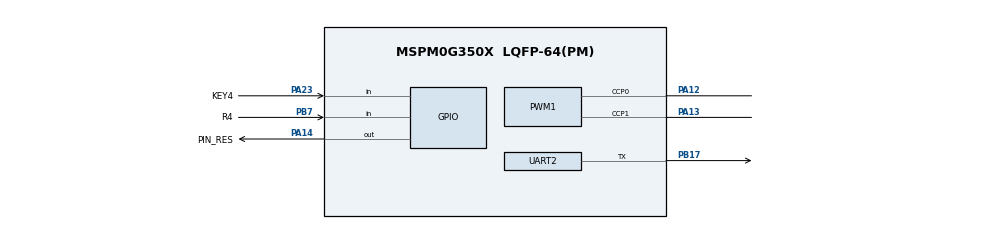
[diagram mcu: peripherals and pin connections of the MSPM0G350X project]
/**
 * @cliArgs --device "MSPM0G350X" --part "Default" --package "LQFP-64(PM)" --product "mspm0_sdk@2.05.01.01"
 * @versions {"tool":"1.24.0+4110"}
 */

/**
 * Import the modules used in this configuration.
 */
const GPIO   = scripting.addModule("/ti/driverlib/GPIO", {}, false);
const GPIO1  = GPIO.addInstance();
const GPIO2  = GPIO.addInstance();
const GPIO3  = GPIO.addInstance();
const GPIO4  = GPIO.addInstance();
const PWM    = scripting.addModule("/ti/driverlib/PWM", {}, false);
const PWM1   = PWM.addInstance();
const SPI    = scripting.addModule("/ti/driverlib/SPI", {}, false);
const SPI1   = SPI.addInstance();
const SYSCTL = scripting.addModule("/ti/driverlib/SYSCTL");
const TIMER  = scripting.addModule("/ti/driverlib/TIMER", {}, false);
const TIMER1 = TIMER.addInstance();
const UART   = scripting.addModule("/ti/driverlib/UART", {}, false);
const UART1  = UART.addInstance();
const UART2  = UART.addInstance();

/**
 * Write custom configuration values to the imported modules.
 */
const divider7       = system.clockTree["PLL_PDIV"];
divider7.divideValue = 2;

const divider9       = system.clockTree["UDIV"];
divider9.divideValue = 2;

const multiplier2         = system.clockTree["PLL_QDIV"];
multiplier2.multiplyValue = 5;

const mux8       = system.clockTree["HSCLKMUX"];
mux8.inputSelect = "HSCLKMUX_SYSPLL2X";

GPIO1.$name                         = "GPIO_OLED";
GPIO1.associatedPins[0].$name       = "PIN_RES";
GPIO1.associatedPins[0].pin.$assign = "PA14";

const Board = scripting.addModule("/ti/driverlib/Board", {}, false);

GPIO2.$name                          = "xunji";
GPIO2.associatedPins.create(8);
GPIO2.associatedPins[0].$name        = "L4";
GPIO2.associatedPins[0].direction    = "INPUT";
GPIO2.associatedPins[0].assignedPort = "PORTA";
GPIO2.associatedPins[0].assignedPin  = "0";
GPIO2.associatedPins[1].$name        = "L3";
GPIO2.associatedPins[1].direction    = "INPUT";
GPIO2.associatedPins[1].assignedPort = "PORTA";
GPIO2.associatedPins[1].assignedPin  = "1";
GPIO2.associatedPins[2].$name        = "L2";
GPIO2.associatedPins[2].direction    = "INPUT";
GPIO2.associatedPins[2].assignedPort = "PORTA";
GPIO2.associatedPins[2].assignedPin  = "28";
GPIO2.associatedPins[3].$name        = "L1";
GPIO2.associatedPins[3].direction    = "INPUT";
GPIO2.associatedPins[3].assignedPort = "PORTA";
GPIO2.associatedPins[3].assignedPin  = "27";
GPIO2.associatedPins[4].$name        = "R1";
GPIO2.associatedPins[4].direction    = "INPUT";
GPIO2.associatedPins[4].assignedPort = "PORTA";
GPIO2.associatedPins[4].assignedPin  = "26";
GPIO2.associatedPins[5].$name        = "R2";
GPIO2.associatedPins[5].direction    = "INPUT";
GPIO2.associatedPins[5].assignedPort = "PORTA";
GPIO2.associatedPins[5].assignedPin  = "25";
GPIO2.associatedPins[6].$name        = "R3";
GPIO2.associatedPins[6].direction    = "INPUT";
GPIO2.associatedPins[6].assignedPort = "PORTA";
GPIO2.associatedPins[6].assignedPin  = "24";
GPIO2.associatedPins[7].$name        = "R4";
GPIO2.associatedPins[7].direction    = "INPUT";
GPIO2.associatedPins[7].assignedPin  = "7";
GPIO2.associatedPins[7].assignedPort = "PORTB";
GPIO2.associatedPins[7].pin.$assign  = "PB7";

GPIO3.$name                          = "motorin";
GPIO3.associatedPins.create(5);
GPIO3.associatedPins[0].$name        = "AIN1";
GPIO3.associatedPins[0].assignedPort = "PORTB";
GPIO3.associatedPins[0].assignedPin  = "8";
GPIO3.associatedPins[1].$name        = "AIN2";
GPIO3.associatedPins[1].assignedPort = "PORTB";
GPIO3.associatedPins[1].assignedPin  = "9";
GPIO3.associatedPins[2].$name        = "BIN1";
GPIO3.associatedPins[2].assignedPort = "PORTA";
GPIO3.associatedPins[2].assignedPin  = "21";
GPIO3.associatedPins[3].$name        = "BIN2";
GPIO3.associatedPins[3].assignedPort = "PORTA";
GPIO3.associatedPins[3].assignedPin  = "22";
GPIO3.associatedPins[4].$name        = "STBY";
GPIO3.associatedPins[4].assignedPort = "PORTA";
GPIO3.associatedPins[4].assignedPin  = "16";

GPIO4.$name                              = "KEYS";
GPIO4.associatedPins.create(4);
GPIO4.associatedPins[0].direction        = "INPUT";
GPIO4.associatedPins[0].assignedPort     = "PORTA";
GPIO4.associatedPins[0].assignedPin      = "2";
GPIO4.associatedPins[0].$name            = "KEY1";
GPIO4.associatedPins[0].internalResistor = "PULL_UP";
GPIO4.associatedPins[1].direction        = "INPUT";
GPIO4.associatedPins[1].$name            = "KEY2";
GPIO4.associatedPins[1].assignedPort     = "PORTB";
GPIO4.associatedPins[1].assignedPin      = "19";
GPIO4.associatedPins[1].internalResistor = "PULL_UP";
GPIO4.associatedPins[2].direction        = "INPUT";
GPIO4.associatedPins[2].assignedPort     = "PORTB";
GPIO4.associatedPins[2].$name            = "KEY3";
GPIO4.associatedPins[2].assignedPin      = "20";
GPIO4.associatedPins[3].$name            = "KEY4";
GPIO4.associatedPins[3].direction        = "INPUT";
GPIO4.associatedPins[3].assignedPort     = "PORTA";
GPIO4.associatedPins[3].assignedPin      = "23";
GPIO4.associatedPins[3].pin.$assign      = "PA23";

PWM1.$name                              = "motorAB";
PWM1.timerCount                         = 32000;
PWM1.pwmMode                            = "EDGE_ALIGN_UP";
PWM1.peripheral.ccp0Pin.$assign         = "PA12";
PWM1.peripheral.ccp1Pin.$assign         = "PA13";
PWM1.PWM_CHANNEL_0.$name                = "ti_driverlib_pwm_PWMTimerCC0";
PWM1.PWM_CHANNEL_1.$name                = "ti_driverlib_pwm_PWMTimerCC1";
PWM1.ccp0PinConfig.direction            = scripting.forceWrite("OUTPUT");
PWM1.ccp0PinConfig.hideOutputInversion  = scripting.forceWrite(false);
PWM1.ccp0PinConfig.onlyInternalResistor = scripting.forceWrite(false);
PWM1.ccp0PinConfig.passedPeripheralType = scripting.forceWrite("Digital");
PWM1.ccp0PinConfig.$name                = "ti_driverlib_gpio_GPIOPinGeneric5";
PWM1.ccp1PinConfig.direction            = scripting.forceWrite("OUTPUT");
PWM1.ccp1PinConfig.hideOutputInversion  = scripting.forceWrite(false);
PWM1.ccp1PinConfig.onlyInternalResistor = scripting.forceWrite(false);
PWM1.ccp1PinConfig.passedPeripheralType = scripting.forceWrite("Digital");
PWM1.ccp1PinConfig.$name                = "ti_driverlib_gpio_GPIOPinGeneric6";

SPI1.$name                              = "SPI_OLED";
SPI1.targetBitRate                      = 10000000;
SPI1.direction                          = "PICO";
SPI1.enableCDMode                       = true;
SPI1.sclkPinConfig.direction            = scripting.forceWrite("OUTPUT");
SPI1.sclkPinConfig.onlyInternalResistor = scripting.forceWrite(false);
SPI1.sclkPinConfig.passedPeripheralType = scripting.forceWrite("Digital");
SPI1.sclkPinConfig.$name                = "ti_driverlib_gpio_GPIOPinGeneric0";
SPI1.mosiPinConfig.direction            = scripting.forceWrite("OUTPUT");
SPI1.mosiPinConfig.hideOutputInversion  = scripting.forceWrite(false);
SPI1.mosiPinConfig.onlyInternalResistor = scripting.forceWrite(false);
SPI1.mosiPinConfig.passedPeripheralType = scripting.forceWrite("Digital");
SPI1.mosiPinConfig.$name                = "ti_driverlib_gpio_GPIOPinGeneric2";
SPI1.cs0PinConfig.direction             = scripting.forceWrite("OUTPUT");
SPI1.cs0PinConfig.hideOutputInversion   = scripting.forceWrite(false);
SPI1.cs0PinConfig.onlyInternalResistor  = scripting.forceWrite(false);
SPI1.cs0PinConfig.passedPeripheralType  = scripting.forceWrite("Digital");
SPI1.cs0PinConfig.$name                 = "ti_driverlib_gpio_GPIOPinGeneric4";
SPI1.cs3PinConfig.$name                 = "ti_driverlib_gpio_GPIOPinGeneric3";

SYSCTL.forceDefaultClkConfig = true;
SYSCTL.clockTreeEn           = true;
scripting.suppress("For best practices when the CPUCLK is running at 32MHz and above, clear the flash status bit using DL_FlashCTL_executeClearStatus\\(\\) before executing any flash operation\\. Otherwise there may be false positives\\.", SYSCTL);

TIMER1.$name            = "TIM_EncoderA";
TIMER1.timerClkPrescale = 256;
TIMER1.timerPeriod      = "100ms";
TIMER1.interrupts       = ["ZERO"];

UART1.$name                            = "UART_WIT";
UART1.targetBaudRate                   = 115200;
UART1.direction                        = "RX";
UART1.enableFIFO                       = true;
UART1.rxTimeoutValue                   = 1;
UART1.enabledInterrupts                = ["RX_TIMEOUT_ERROR"];
UART1.enabledDMARXTriggers             = "DL_UART_DMA_INTERRUPT_RX";
UART1.rxPinConfig.hideOutputInversion  = scripting.forceWrite(false);
UART1.rxPinConfig.onlyInternalResistor = scripting.forceWrite(false);
UART1.rxPinConfig.passedPeripheralType = scripting.forceWrite("Digital");
UART1.rxPinConfig.$name                = "ti_driverlib_gpio_GPIOPinGeneric1";
UART1.DMA_CHANNEL_RX.$name             = "DMA_WIT";
UART1.DMA_CHANNEL_RX.srcLength         = "BYTE";
UART1.DMA_CHANNEL_RX.dstLength         = "BYTE";
UART1.DMA_CHANNEL_RX.addressMode       = "f2b";

UART2.$name                            = "UART_0";
UART2.targetBaudRate                   = 115200;
UART2.peripheral.txPin.$assign         = "PB17";
UART2.txPinConfig.direction            = scripting.forceWrite("OUTPUT");
UART2.txPinConfig.hideOutputInversion  = scripting.forceWrite(false);
UART2.txPinConfig.onlyInternalResistor = scripting.forceWrite(false);
UART2.txPinConfig.passedPeripheralType = scripting.forceWrite("Digital");
UART2.txPinConfig.$name                = "ti_driverlib_gpio_GPIOPinGeneric7";
UART2.rxPinConfig.hideOutputInversion  = scripting.forceWrite(false);
UART2.rxPinConfig.onlyInternalResistor = scripting.forceWrite(false);
UART2.rxPinConfig.passedPeripheralType = scripting.forceWrite("Digital");
UART2.rxPinConfig.$name                = "ti_driverlib_gpio_GPIOPinGeneric8";

/**
 * Pinmux solution for unlocked pins/peripherals. This ensures that minor changes to the automatic solver in a future
 * version of the tool will not impact the pinmux you originally saw.  These lines can be completely deleted in order to
 * re-solve from scratch.
 */
Board.peripheral.$suggestSolution                = "DEBUGSS";
Board.peripheral.swclkPin.$suggestSolution       = "PA20";
Board.peripheral.swdioPin.$suggestSolution       = "PA19";
GPIO2.associatedPins[0].pin.$suggestSolution     = "PA0";
GPIO2.associatedPins[1].pin.$suggestSolution     = "PA1";
GPIO2.associatedPins[2].pin.$suggestSolution     = "PA28";
GPIO2.associatedPins[3].pin.$suggestSolution     = "PA27";
GPIO2.associatedPins[4].pin.$suggestSolution     = "PA26";
GPIO2.associatedPins[5].pin.$suggestSolution     = "PA25";
GPIO2.associatedPins[6].pin.$suggestSolution     = "PA24";
GPIO3.associatedPins[0].pin.$suggestSolution     = "PB8";
GPIO3.associatedPins[1].pin.$suggestSolution     = "PB9";
GPIO3.associatedPins[2].pin.$suggestSolution     = "PA21";
GPIO3.associatedPins[3].pin.$suggestSolution     = "PA22";
GPIO3.associatedPins[4].pin.$suggestSolution     = "PA16";
GPIO4.associatedPins[0].pin.$suggestSolution     = "PA2";
GPIO4.associatedPins[1].pin.$suggestSolution     = "PB19";
GPIO4.associatedPins[2].pin.$suggestSolution     = "PB20";
PWM1.peripheral.$suggestSolution                 = "TIMG0";
SPI1.peripheral.$suggestSolution                 = "SPI0";
SPI1.peripheral.sclkPin.$suggestSolution         = "PA6";
SPI1.peripheral.mosiPin.$suggestSolution         = "PA5";
SPI1.peripheral.cs0Pin.$suggestSolution          = "PA8";
SPI1.peripheral.cs3Pin.$suggestSolution          = "PB14";
TIMER1.peripheral.$suggestSolution               = "TIMA0";
UART1.peripheral.$suggestSolution                = "UART0";
UART1.peripheral.rxPin.$suggestSolution          = "PA11";
UART1.DMA_CHANNEL_RX.peripheral.$suggestSolution = "DMA_CH0";
UART2.peripheral.$suggestSolution                = "UART2";
UART2.peripheral.rxPin.$suggestSolution          = "PB16";
